# ADSP-2183xW_HPC register map
Vendor: Analog Devices; Series: ADSP-2183xW_HPC; File version: 3.0.3.517
CPU: 
Registers are 32-bit, read-write, reset 0x0 unless marked. A register's access mark holds for its fields unless they carry their own. Offsets are from the block's base; [hi:lo] are bit positions; {n}, {i} and the like mark numbered series; 'fields as' and 'values as' point back to an identical list.

## TRNG0 — True Random Number Generator
Base 0x310D0000
0x00 INPUT[0] — TRNG Input Registers
  [31:0] VALUE range 0x00000000..0xFFFFFFFF — Input Bits for 32-bit Word n
{0x0+4i} OUTPUT[{i}] (i=0..3) — TRNG Output Registers
  [31:0] VALUE range 0x00000000..0xFFFFFFFF — Output Bits for 32-bit Word n
0x04 INPUT[1] — TRNG Input Registers
  fields as INPUT[0]
0x10 INTACK — TRNG Interrupt Acknowledge Register
  [7] MBITFAIL range 0x00000000..0x00000001 — Monobit Fail Acknowledge
  [6] PKRFAIL range 0x00000000..0x00000001 — Poker Fail Acknowledge
  [5] LRUNFAIL range 0x00000000..0x00000001 — Long Run Fail Acknowledge
  [4] RUNFAIL range 0x00000000..0x00000001 — Run Fail Acknowledge
  [3] NOISEFAIL range 0x00000000..0x00000001 — Noise Fail Acknowledge
  [2] STUCKOUT range 0x00000000..0x00000001 — Stuck Out Acknowledge
  [1] SHDNOVR range 0x00000000..0x00000001 — Shutdown Overflow Acknowledge
  [7:0] OPENRDGATE range 0x00000000..0x000000FF — Open Read Gate
  [0] RDY range 0x00000000..0x00000001 — Ready Acknowledge
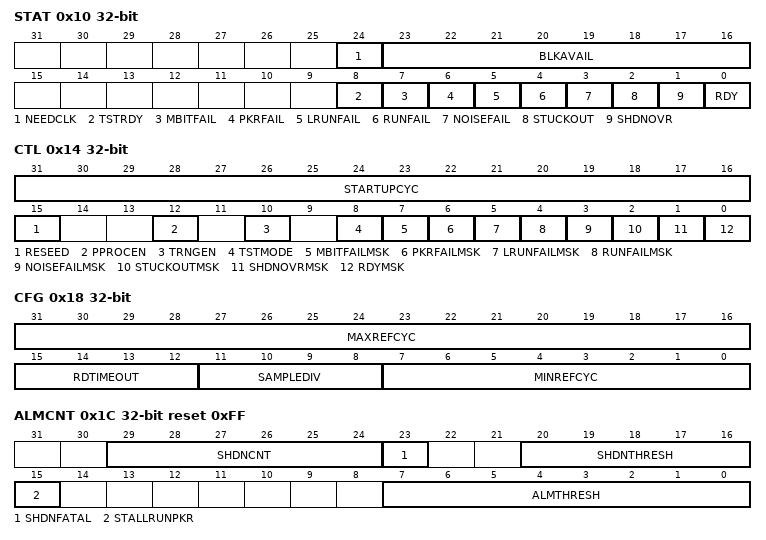
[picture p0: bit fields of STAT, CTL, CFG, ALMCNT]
0x10 STAT (alternate view of INTACK) — TRNG Status Register
  [24] NEEDCLK ro — Need Clock
  [23:16] BLKAVAIL ro — Blocks Available
  [8] TSTRDY ro — Test Ready
  [7] MBITFAIL ro — Monobit Fail
  [6] PKRFAIL ro — Poker Fail
  [5] LRUNFAIL ro — Long Run Fail
  [4] RUNFAIL ro
  [3] NOISEFAIL ro
  [2] STUCKOUT ro
  [1] SHDNOVR ro — Shutdown Overflow
  [0] RDY ro — Ready
0x14 CTL — TRNG Control Register
  [31:16] STARTUPCYC range 0x00000000..0x0000FFFF — Startup Cycles
  [15] RESEED range 0x00000000..0x00000001
  [12] PPROCEN range 0x00000000..0x00000001 — Post Processor Enable
  [10] TRNGEN range 0x00000000..0x00000001 — Enable TRNG
  [8] TSTMODE range 0x00000000..0x00000001 — Test Mode
  [7] MBITFAILMSK range 0x00000000..0x00000001 — Monobit Fail Mask
  [6] PKRFAILMSK range 0x00000000..0x00000001 — Poker Fail Mask
  [5] LRUNFAILMSK range 0x00000000..0x00000001 — Long Run Fail Mask
  [4] RUNFAILMSK range 0x00000000..0x00000001 — Run Fail Mask
  [3] NOISEFAILMSK range 0x00000000..0x00000001 — Noise Fail Mask
  [2] STUCKOUTMSK range 0x00000000..0x00000001 — Stuck Out Mask
  [1] SHDNOVRMSK range 0x00000000..0x00000001 — Shutdown Overflow Mask
  [0] RDYMSK range 0x00000000..0x00000001 — Ready Mask
0x18 CFG — TRNG Configuration Register
  [31:16] MAXREFCYC range 0x00000000..0x0000FFFF — Max Refill Cycles
  [15:12] RDTIMEOUT range 0x00000000..0x0000000F — Read Timeout
  [11:8] SAMPLEDIV range 0x00000000..0x0000000F
  [7:0] MINREFCYC range 0x00000000..0x000000FF — Min Refill Cycles
0x1C ALMCNT reset 0xFF — TRNG Alarm Counter Register
  [29:24] SHDNCNT ro — Shutdown Count
  [23] SHDNFATAL range 0x00000000..0x00000001 — Shutdown Fatal
  [20:16] SHDNTHRESH range 0x00000000..0x0000001F — Shutdown Threshold
  [15] STALLRUNPKR range 0x00000000..0x00000001 — Stall Run Poker
  [7:0] ALMTHRESH range 0x00000000..0x000000FF — Alarm Threshold
0x20 FROEN reset 0xFF — TRNG FRO Enable Register
  [7:0] FROS range 0x00000000..0x000000FF — Enable Free-Running Oscillators
0x24 FRODETUNE — TRNG FRO De-tune Register
  [7:0] FROS range 0x00000000..0x000000FF — FRO De-tune Bits
0x28 ALMMSK — TRNG Alarm Mask Register
  [7:0] FROS range 0x00000000..0x000000FF — FRO Alarm Mask
0x2C ALMSTP — TRNG Alarm Stop Register
  [7:0] FROS range 0x00000000..0x000000FF — FRO Alarm Stop Bits
0x30 LFSR_L — TRNG LFSR Access Register
  [31:0] VALUE range 0x00000000..0xFFFFFFFF — LFSR[31:0]
0x34 LFSR_M — TRNG LFSR Access Register
  [31:0] VALUE range 0x00000000..0xFFFFFFFF — LFSR[63:32]
0x38 LFSR_H — TRNG LFSR Access Register
  [16:0] VALUE range 0x00000000..0x0001FFFF — LFSR[80:64]
0x3C CNT — Counter Register
  [23:0] VALUE range 0x00000000..0x00FFFFFF — Sample Counter
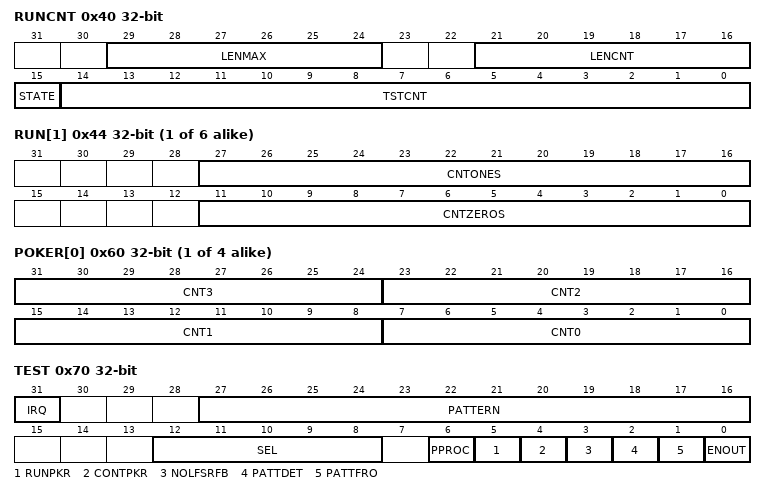
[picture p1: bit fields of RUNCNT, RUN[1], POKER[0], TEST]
0x40 RUNCNT — TRNG Run Count Registers
  [29:24] LENMAX ro — Run Length Max
  [21:16] LENCNT ro — Run Length Br Count
  [15] STATE ro — Run State
  [14:0] TSTCNT ro — Run Test Count
{0x40+4i} KEY[{i}] (i=0..5) — Post-Process Key Registers
  [31:0] VALUE range 0x00000000..0xFFFFFFFF — Key bits
{0x40+4i} RUN[{i}] (i=1..6) — TRNG Run Test State and Result Registers
  [27:16] CNTONES ro — Count Ones
  [11:0] CNTZEROS ro — Count Zeros
0x5C MONOBITCNT reset 0x2710 — TRNG Monobit Test Result Register
  [16:0] VALUE ro — Monobit Count
{0x60+4i} POKER[{i}] (i=0..3) — TRNG Poker Test Result Registers
  [31:24] CNT3 ro — Poker Count n + 3
  [23:16] CNT2 ro — Poker Count n + 2
  [15:8] CNT1 ro — Poker Count n + 1
  [7:0] CNT0 ro — Poker Count n
0x60 V[0] — TRNG Post-Process "V" Value Registers
  [31:0] VALUE wo range 0x00000000..0xFFFFFFFF — Holds "V" value for post-processing
0x64 V[1] — TRNG Post-Process "V" Value Registers
  fields as V[0]
0x70 TEST — TRNG Test Register
  [31] IRQ — Test IRQ
  [27:16] PATTERN range 0x00000000..0x00000FFF — Test Pattern
  [12:8] SEL range 0x00000000..0x0000001F — Test Select
  [6] PPROC range 0x00000000..0x00000001 — Test Post Proc
  [5] RUNPKR range 0x00000000..0x00000001 — Test Run Poker
  [4] CONTPKR — Continue Poker
  [3] NOLFSRFB — No LFSR Feedback
  [2] PATTDET — Test Pattern Detect
  [1] PATTFRO — Test Pattern FRO
  [0] ENOUT — Test Enable Out
0x74 BLKCNT — TRNG Block Count Register
  [31:4] VALUE range 0x00000000..0x0FFFFFFF — Block Count
